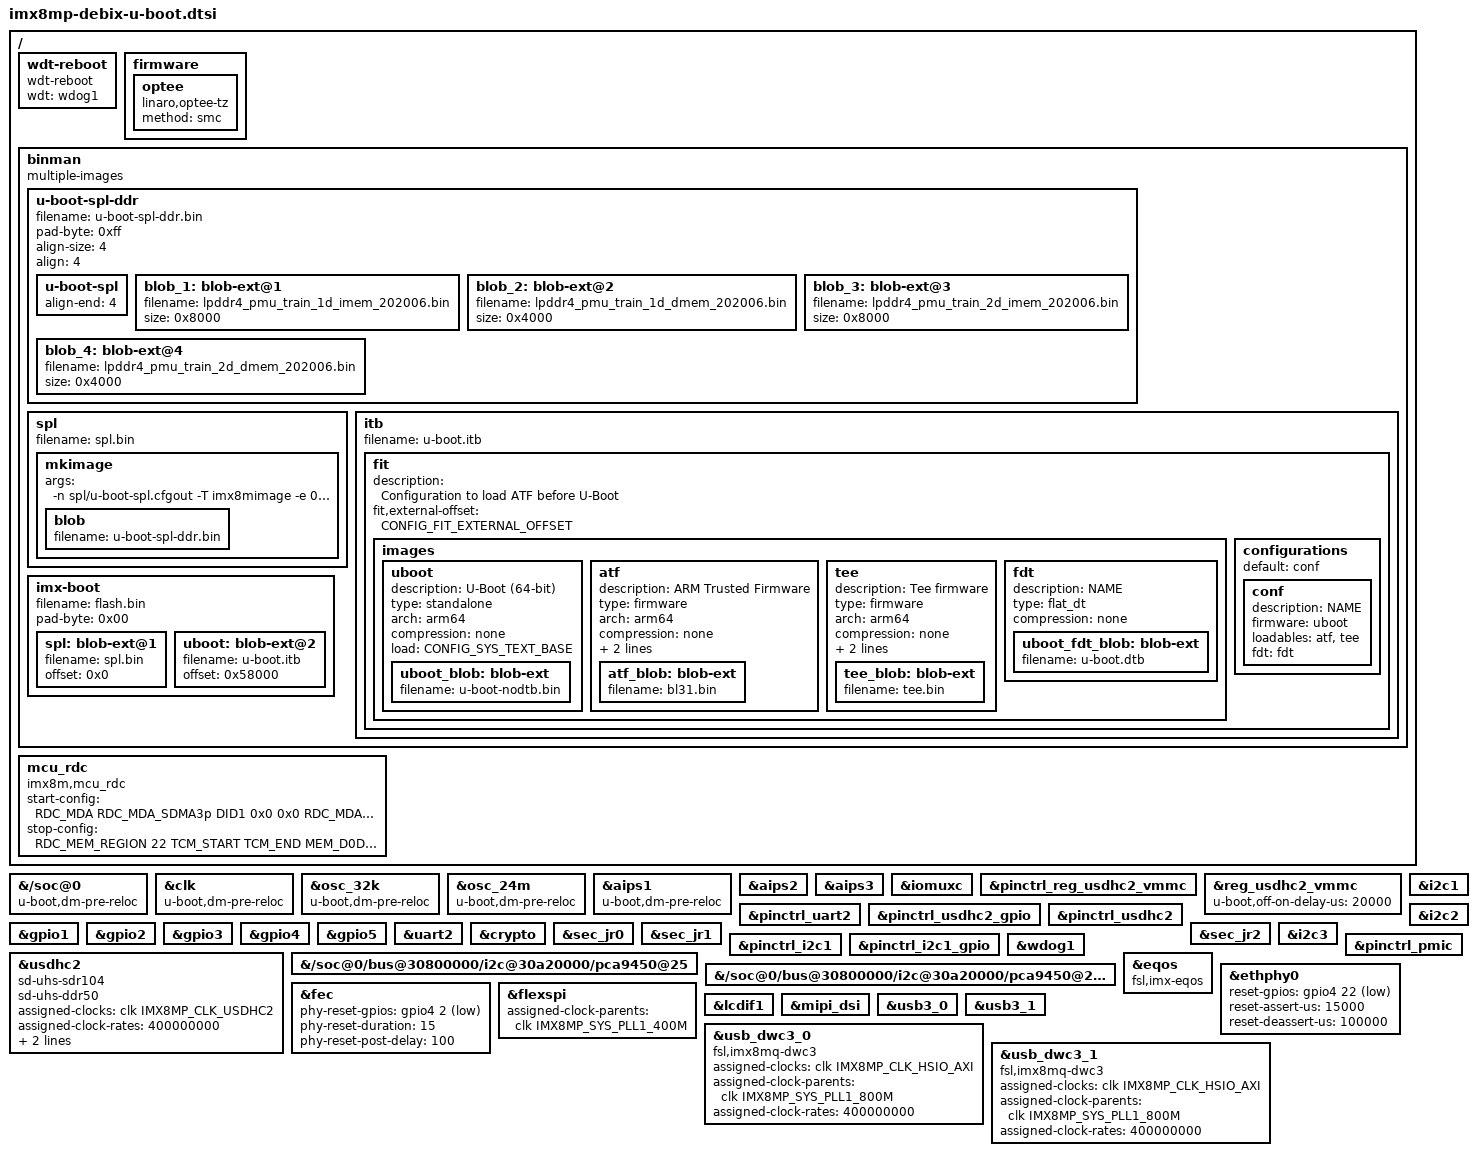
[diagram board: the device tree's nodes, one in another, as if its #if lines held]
// SPDX-License-Identifier: GPL-2.0+
/*
 * Copyright 2023 Joris Offouga
 */
#include "imx8mp-sec-def.h"

/ {
	wdt-reboot {
		compatible = "wdt-reboot";
		wdt = <&wdog1>;
		u-boot,dm-spl;
	};

#ifdef CONFIG_IMX_OPTEE_DEK_ENCAP
	firmware {
		optee {
			compatible = "linaro,optee-tz";
			method = "smc";
		};
	};
#endif

	binman: binman {
		multiple-images;
	};

	mcu_rdc {
		compatible = "imx8m,mcu_rdc";
			    /* rdc config when MCU starts
			     * master
			     *   SDMA3p --> domain 1
			     *   SDMA3b --> domian 1
			     *   SDMA3_SPBA2  --> domian 1
			     * peripheral:
			     *   SAI3   --> Only Domian 1 can access
			     *   UART4  --> Only Domian 1 can access
			     *   GPT1   --> Only Domian 1 can access
			     *   SDMA3  --> Only Domian 1 can access
			     *   I2C3   --> Only Domian 1 can access
			     * memory:
			     *   TCM    --> Only Domian 1 can access (0x7E0000~0x81FFFF)
			     *   DDR    --> Only Domian 1 can access (0x80000000~0x81000000)
			     * end.
			     */
		start-config = <
			    RDC_MDA  RDC_MDA_SDMA3p DID1 0x0 0x0
			    RDC_MDA  RDC_MDA_ENET1_TX DID1 0x0 0x0
			    RDC_MDA  RDC_MDA_ENET1_RX DID1 0x0 0x0
			    RDC_MDA  RDC_MDA_SDMA3b DID1 0x0 0x0
			    RDC_MDA  RDC_MDA_SDMA3_SPBA2 DID1 0x0 0x0
			    RDC_PDAP RDC_PDAP_ENET1 PDAP_D0D1_ACCESS 0x0 0x0
			    RDC_PDAP RDC_PDAP_SAI3  PDAP_D1_ACCESS 0x0 0x0
			    RDC_PDAP RDC_PDAP_UART4 PDAP_D1_ACCESS 0x0 0x0
			    RDC_PDAP RDC_PDAP_GPT1  PDAP_D1_ACCESS 0x0 0x0
			    RDC_PDAP RDC_PDAP_SDMA3 PDAP_D1_ACCESS 0x0 0x0
			    RDC_PDAP RDC_PDAP_I2C3  PDAP_D1_ACCESS 0x0 0x0
			    RDC_MEM_REGION 22 TCM_START TCM_END MEM_D1_ACCESS
			    RDC_MEM_REGION 39 M4_DDR_START M4_DDR_END MEM_D1_ACCESS
			    0x0      0x0            0x0  0x0 0x0
			  >;
			    /* rdc config when MCU stops
			     * memory:
			     *   TCM    --> domain 0/1 can access (0x7E0000~0x81FFFF)
			     *   DDR    --> domain 0/1 can access (0x80000000~0x81000000)
			     * end.
			     */
		stop-config = <
			    RDC_MEM_REGION 22 TCM_START TCM_END MEM_D0D1_ACCESS
			    RDC_MEM_REGION 39 M4_DDR_START M4_DDR_END MEM_D0D1_ACCESS
			    0x0      0x0            0x0  0x0 0x0
			  >;
	};
};

&{/soc@0} {
	u-boot,dm-pre-reloc;
	u-boot,dm-spl;
};

&clk {
	u-boot,dm-spl;
	u-boot,dm-pre-reloc;
	/delete-property/ assigned-clocks;
	/delete-property/ assigned-clock-parents;
	/delete-property/ assigned-clock-rates;
};

&osc_32k {
	u-boot,dm-spl;
	u-boot,dm-pre-reloc;
};

&osc_24m {
	u-boot,dm-spl;
	u-boot,dm-pre-reloc;
};

&aips1 {
	u-boot,dm-spl;
	u-boot,dm-pre-reloc;
};

&aips2 {
	u-boot,dm-spl;
};

&aips3 {
	u-boot,dm-spl;
};

&iomuxc {
	u-boot,dm-spl;
};

&pinctrl_reg_usdhc2_vmmc {
	u-boot,dm-spl;
};

&reg_usdhc2_vmmc {
	u-boot,dm-spl;
	u-boot,off-on-delay-us = <20000>;
};

&pinctrl_uart2 {
	u-boot,dm-spl;
};

&pinctrl_usdhc2_gpio {
	u-boot,dm-spl;
};

&pinctrl_usdhc2 {
	u-boot,dm-spl;
};

&gpio1 {
	u-boot,dm-spl;
};

&gpio2 {
	u-boot,dm-spl;
};

&gpio3 {
	u-boot,dm-spl;
};

&gpio4 {
	u-boot,dm-spl;
};

&gpio5 {
	u-boot,dm-spl;
};

&uart2 {
	u-boot,dm-spl;
};

&crypto {
	u-boot,dm-spl;
};

&sec_jr0 {
	u-boot,dm-spl;
};

&sec_jr1 {
	u-boot,dm-spl;
};

&sec_jr2 {
	u-boot,dm-spl;
};

&i2c1 {
	u-boot,dm-spl;
};

&i2c2 {
	u-boot,dm-spl;
};

&i2c3 {
	u-boot,dm-spl;
};

&pinctrl_i2c1 {
	u-boot,dm-spl;
};

&pinctrl_i2c1_gpio {
	u-boot,dm-spl;
};


&usdhc2 {
	u-boot,dm-spl;
	sd-uhs-sdr104;
	sd-uhs-ddr50;
	assigned-clocks = <&clk IMX8MP_CLK_USDHC2>;
	assigned-clock-rates = <400000000>;
	assigned-clock-parents = <&clk IMX8MP_SYS_PLL1_400M>;
};


&wdog1 {
	u-boot,dm-spl;
};

&{/soc@0/bus@30800000/i2c@30a20000/pca9450@25} {
	u-boot,dm-spl;
};

&{/soc@0/bus@30800000/i2c@30a20000/pca9450@25/regulators} {
	u-boot,dm-spl;
};

&pinctrl_pmic {
	u-boot,dm-spl;
};

&eqos {
	compatible = "fsl,imx-eqos";
	/delete-property/ assigned-clocks;
	/delete-property/ assigned-clock-parents;
	/delete-property/ assigned-clock-rates;
};

&ethphy0 {
	reset-gpios = <&gpio4 22 GPIO_ACTIVE_LOW>;
	reset-assert-us = <15000>;
	reset-deassert-us = <100000>;
};

&fec {
	phy-reset-gpios = <&gpio4 2 GPIO_ACTIVE_LOW>;
	phy-reset-duration = <15>;
	phy-reset-post-delay = <100>;
};

&flexspi {
	assigned-clock-parents = <&clk IMX8MP_SYS_PLL1_400M>;
};

&lcdif1 {
	/delete-property/ assigned-clocks;
	/delete-property/ assigned-clock-parents;
	/delete-property/ assigned-clock-rates;
};

&mipi_dsi {
	/delete-property/ assigned-clocks;
	/delete-property/ assigned-clock-parents;
	/delete-property/ assigned-clock-rates;
};

&usb3_0 {
	/delete-property/ power-domains;
};

&usb3_1 {
	/delete-property/ power-domains;
};

&usb_dwc3_0 {
	compatible = "fsl,imx8mq-dwc3", "snps,dwc3";
	assigned-clocks = <&clk IMX8MP_CLK_HSIO_AXI>;
	assigned-clock-parents = <&clk IMX8MP_SYS_PLL1_800M>;
	assigned-clock-rates = <400000000>;
};

&usb_dwc3_1 {
	compatible = "fsl,imx8mq-dwc3", "snps,dwc3";
	assigned-clocks = <&clk IMX8MP_CLK_HSIO_AXI>;
	assigned-clock-parents = <&clk IMX8MP_SYS_PLL1_800M>;
	assigned-clock-rates = <400000000>;
};

&binman {
	 u-boot-spl-ddr {
		filename = "u-boot-spl-ddr.bin";
		pad-byte = <0xff>;
		align-size = <4>;
		align = <4>;

		u-boot-spl {
			align-end = <4>;
		};

		blob_1: blob-ext@1 {
			filename = "lpddr4_pmu_train_1d_imem_202006.bin";
			size = <0x8000>;
		};

		blob_2: blob-ext@2 {
			filename = "lpddr4_pmu_train_1d_dmem_202006.bin";
			size = <0x4000>;
		};

		blob_3: blob-ext@3 {
			filename = "lpddr4_pmu_train_2d_imem_202006.bin";
			size = <0x8000>;
		};

		blob_4: blob-ext@4 {
			filename = "lpddr4_pmu_train_2d_dmem_202006.bin";
			size = <0x4000>;
		};
	};

	spl {
		filename = "spl.bin";

		mkimage {
			args = "-n spl/u-boot-spl.cfgout -T imx8mimage -e 0x920000";

			blob {
				filename = "u-boot-spl-ddr.bin";
			};
		};
	};

	itb {
		filename = "u-boot.itb";

		fit {
			description = "Configuration to load ATF before U-Boot";
			#address-cells = <1>;
			fit,external-offset = <CONFIG_FIT_EXTERNAL_OFFSET>;

			images {
				uboot {
					description = "U-Boot (64-bit)";
					type = "standalone";
					arch = "arm64";
					compression = "none";
					load = <CONFIG_SYS_TEXT_BASE>;

					uboot_blob: blob-ext {
						filename = "u-boot-nodtb.bin";
					};
				};

				atf {
					description = "ARM Trusted Firmware";
					type = "firmware";
					arch = "arm64";
					compression = "none";
					load = <0x970000>;
					entry = <0x970000>;

					atf_blob: blob-ext {
						filename = "bl31.bin";
					};
				};
#ifdef CONFIG_IMX_OPTEE_DEK_ENCAP
				tee {
					description = "Tee firmware";
					type = "firmware";
					arch = "arm64";
					compression = "none";
					load = <0x56000000>;
					entry = <0x56000000>;
					tee_blob: blob-ext {
						filename = "tee.bin";
					};
				};
#endif
				fdt {
					description = "NAME";
					type = "flat_dt";
					compression = "none";

					uboot_fdt_blob: blob-ext {
						filename = "u-boot.dtb";
					};
				};
			};

			configurations {
				default = "conf";

				conf {
					description = "NAME";
					firmware = "uboot";
#ifdef CONFIG_IMX_OPTEE_DEK_ENCAP
					loadables = "atf", "tee";
#else
					loadables = "atf";
#endif
					fdt = "fdt";
				};
			};
		};
	};

	imx-boot {
		filename = "flash.bin";
		pad-byte = <0x00>;

		spl: blob-ext@1 {
			filename = "spl.bin";
			offset = <0x0>;
		};

		uboot: blob-ext@2 {
			filename = "u-boot.itb";
			offset = <0x58000>;
		};
	};
};
